VERSION ""

NS_ :

BS_:

BU_:

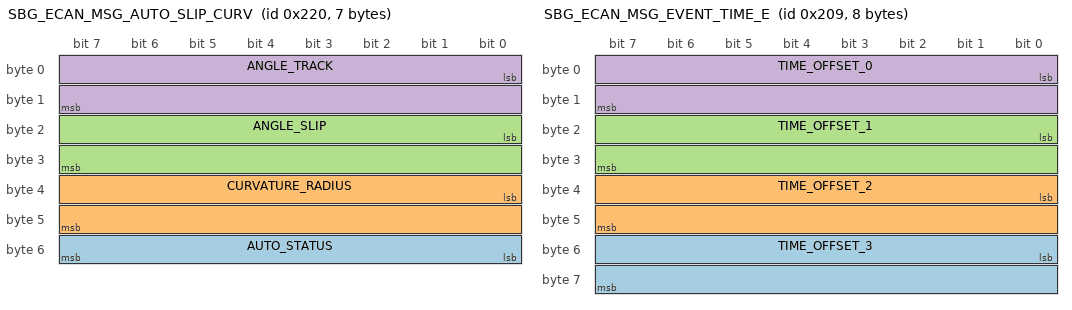
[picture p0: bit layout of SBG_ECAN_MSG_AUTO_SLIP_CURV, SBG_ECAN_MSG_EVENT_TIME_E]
BO_ 544 SBG_ECAN_MSG_AUTO_SLIP_CURV: 7 Vector__XXX
 SG_ AUTO_STATUS : 48|8@1+ (1,0) [0|255] "" Vector__XXX
 SG_ CURVATURE_RADIUS : 32|16@1+ (0.01,0) [0|655.35] "m" Vector__XXX
 SG_ ANGLE_SLIP : 16|16@1- (0.0001,0) [-3.2768|3.2767] "rad" Vector__XXX
 SG_ ANGLE_TRACK : 0|16@1- (0.0001,0) [-3.2768|3.2767] "rad" Vector__XXX

BO_ 521 SBG_ECAN_MSG_EVENT_TIME_E: 8 Vector__XXX
 SG_ TIME_OFFSET_3 : 48|16@1+ (1,0) [0|65535] "µs" Vector__XXX
 SG_ TIME_OFFSET_2 : 32|16@1+ (1,0) [0|65535] "µs" Vector__XXX
 SG_ TIME_OFFSET_1 : 16|16@1+ (1,0) [0|65535] "µs" Vector__XXX
 SG_ TIME_OFFSET_0 : 0|16@1+ (1,0) [0|65535] "µs" Vector__XXX

BO_ 520 SBG_ECAN_MSG_EVENT_INFO_E: 8 Vector__XXX
 SG_ STATUS : 32|16@1+ (1,0) [0|65535] "" Vector__XXX
 SG_ TIME_STAMP : 0|32@1+ (1,0) [0|4294970000] "µs" Vector__XXX

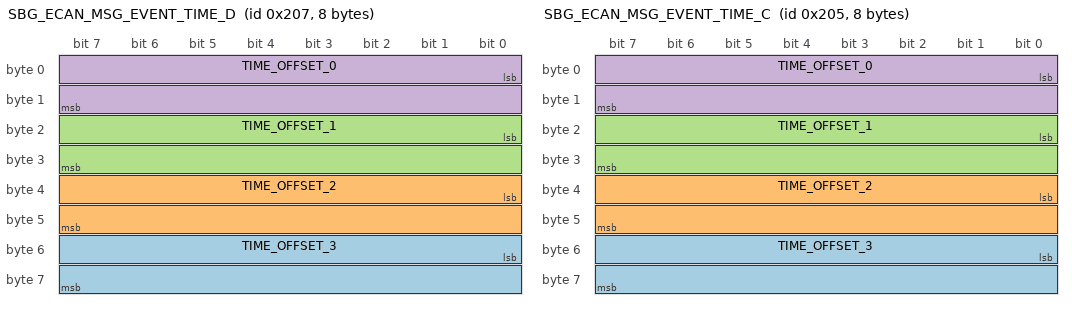
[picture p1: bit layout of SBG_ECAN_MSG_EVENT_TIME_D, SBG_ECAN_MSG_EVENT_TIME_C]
BO_ 519 SBG_ECAN_MSG_EVENT_TIME_D: 8 Vector__XXX
 SG_ TIME_OFFSET_3 : 48|16@1+ (1,0) [0|65535] "µs" Vector__XXX
 SG_ TIME_OFFSET_2 : 32|16@1+ (1,0) [0|65535] "µs" Vector__XXX
 SG_ TIME_OFFSET_1 : 16|16@1+ (1,0) [0|65535] "µs" Vector__XXX
 SG_ TIME_OFFSET_0 : 0|16@1+ (1,0) [0|65535] "µs" Vector__XXX

BO_ 518 SBG_ECAN_MSG_EVENT_INFO_D: 8 Vector__XXX
 SG_ STATUS : 32|16@1+ (1,0) [0|65535] "" Vector__XXX
 SG_ TIME_STAMP : 0|32@1+ (1,0) [0|4294970000] "µs" Vector__XXX

BO_ 517 SBG_ECAN_MSG_EVENT_TIME_C: 8 Vector__XXX
 SG_ TIME_OFFSET_3 : 48|16@1+ (1,0) [0|65535] "µs" Vector__XXX
 SG_ TIME_OFFSET_2 : 32|16@1+ (1,0) [0|65535] "µs" Vector__XXX
 SG_ TIME_OFFSET_1 : 16|16@1+ (1,0) [0|65535] "µs" Vector__XXX
 SG_ TIME_OFFSET_0 : 0|16@1+ (1,0) [0|65535] "µs" Vector__XXX

BO_ 516 SBG_ECAN_MSG_EVENT_INFO_C: 8 Vector__XXX
 SG_ STATUS : 32|16@1+ (1,0) [0|65535] "" Vector__XXX
 SG_ TIME_STAMP : 0|32@1+ (1,0) [0|4294970000] "µs" Vector__XXX

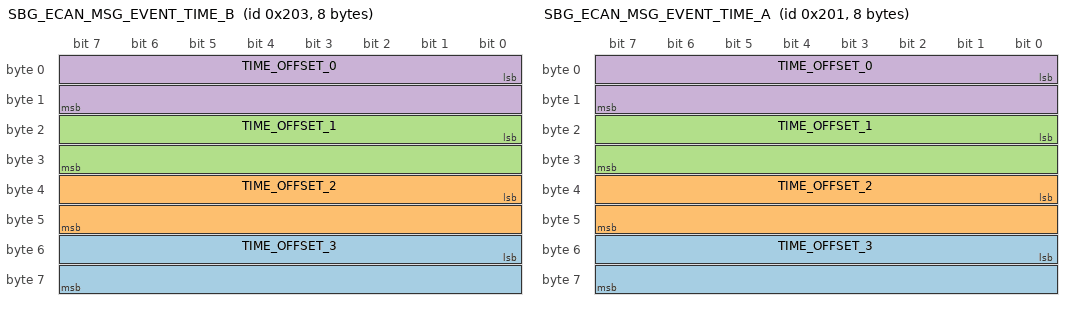
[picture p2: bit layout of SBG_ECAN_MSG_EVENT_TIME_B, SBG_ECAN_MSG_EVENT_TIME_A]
BO_ 515 SBG_ECAN_MSG_EVENT_TIME_B: 8 Vector__XXX
 SG_ TIME_OFFSET_3 : 48|16@1+ (1,0) [0|65535] "µs" Vector__XXX
 SG_ TIME_OFFSET_2 : 32|16@1+ (1,0) [0|65535] "µs" Vector__XXX
 SG_ TIME_OFFSET_1 : 16|16@1+ (1,0) [0|65535] "µs" Vector__XXX
 SG_ TIME_OFFSET_0 : 0|16@1+ (1,0) [0|65535] "µs" Vector__XXX

BO_ 514 SBG_ECAN_MSG_EVENT_INFO_B: 8 Vector__XXX
 SG_ STATUS : 32|16@1+ (1,0) [0|65535] "" Vector__XXX
 SG_ TIME_STAMP : 0|32@1+ (1,0) [0|4294970000] "µs" Vector__XXX

BO_ 513 SBG_ECAN_MSG_EVENT_TIME_A: 8 Vector__XXX
 SG_ TIME_OFFSET_3 : 48|16@1+ (1,0) [0|65535] "µs" Vector__XXX
 SG_ TIME_OFFSET_2 : 32|16@1+ (1,0) [0|65535] "µs" Vector__XXX
 SG_ TIME_OFFSET_1 : 16|16@1+ (1,0) [0|65535] "µs" Vector__XXX
 SG_ TIME_OFFSET_0 : 0|16@1+ (1,0) [0|65535] "µs" Vector__XXX

BO_ 512 SBG_ECAN_MSG_EVENT_INFO_A: 8 Vector__XXX
 SG_ STATUS : 32|16@1+ (1,0) [0|65535] "" Vector__XXX
 SG_ TIME_STAMP : 0|32@1+ (1,0) [0|4294970000] "µs" Vector__XXX

BO_ 396 SBG_ECAN_MSG_GPS2_POS_MON: 5 Vector__XXX
 SG_ UP_TIME : 8|32@1+ (1,0) [0|4294970000] "s" Vector__XXX
 SG_ NR_DIAG_REBOOTS : 0|1@1+ (1,0) [0|255] "" Vector__XXX

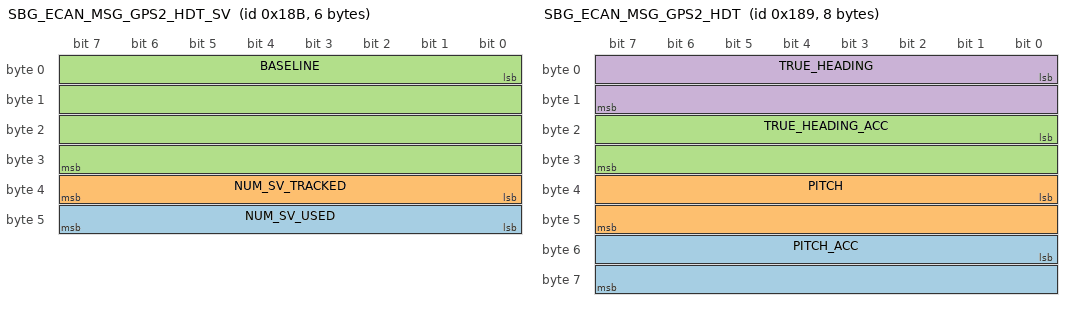
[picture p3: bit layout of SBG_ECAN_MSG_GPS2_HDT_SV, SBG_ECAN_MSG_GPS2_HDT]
BO_ 395 SBG_ECAN_MSG_GPS2_HDT_SV: 6 Vector__XXX
 SG_ NUM_SV_USED : 40|8@1+ (1,0) [0|255] "" Vector__XXX
 SG_ NUM_SV_TRACKED : 32|8@1+ (1,0) [0|255] "" Vector__XXX
 SG_ BASELINE : 0|32@1+ (1,0) [0|4294970000] "m" Vector__XXX

BO_ 394 SBG_ECAN_MSG_GPS2_POS_SECURITY_STATUS: 4 Vector__XXX
 SG_ STATUS : 32|32@1+ (1,0) [0|4294970000] "" Vector__XXX

BO_ 393 SBG_ECAN_MSG_GPS2_HDT: 8 Vector__XXX
 SG_ PITCH_ACC : 48|16@1+ (0.01,0) [0|655.35] "°" Vector__XXX
 SG_ PITCH : 32|16@1- (0.01,0) [-327.68|327.67] "°" Vector__XXX
 SG_ TRUE_HEADING_ACC : 16|16@1+ (0.01,0) [0|655.35] "°" Vector__XXX
 SG_ TRUE_HEADING : 0|16@1+ (0.01,0) [0|655.35] "°" Vector__XXX

BO_ 392 SBG_ECAN_MSG_GPS2_HDT_INFO: 6 Vector__XXX
 SG_ STATUS : 32|16@1+ (1,0) [0|65535] "" Vector__XXX
 SG_ TIME_STAMP : 0|32@1+ (1,0) [0|4294970000] "µs" Vector__XXX

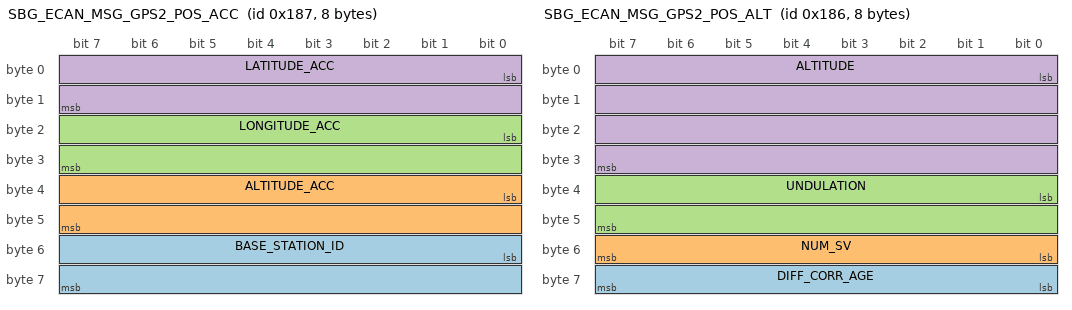
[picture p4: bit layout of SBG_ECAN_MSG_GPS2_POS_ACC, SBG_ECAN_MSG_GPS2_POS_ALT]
BO_ 391 SBG_ECAN_MSG_GPS2_POS_ACC: 8 Vector__XXX
 SG_ BASE_STATION_ID : 48|16@1+ (1,0) [0|65535] "" Vector__XXX
 SG_ ALTITUDE_ACC : 32|16@1+ (0.01,0) [0|655.35] "m" Vector__XXX
 SG_ LONGITUDE_ACC : 16|16@1+ (0.01,0) [0|655.35] "m" Vector__XXX
 SG_ LATITUDE_ACC : 0|16@1+ (0.01,0) [0|655.35] "m" Vector__XXX

BO_ 390 SBG_ECAN_MSG_GPS2_POS_ALT: 8 Vector__XXX
 SG_ DIFF_CORR_AGE : 56|8@1+ (1,0) [0|255] "s" Vector__XXX
 SG_ NUM_SV : 48|8@1+ (1,0) [0|255] "" Vector__XXX
 SG_ UNDULATION : 32|16@1- (0.005,0) [-163.84|163.835] "m" Vector__XXX
 SG_ ALTITUDE : 0|32@1- (0.001,0) [-2147480|2147480] "m" Vector__XXX

BO_ 389 SBG_ECAN_MSG_GPS2_POS: 8 Vector__XXX
 SG_ LONGITUDE : 32|32@1- (1E-007,0) [-214.7483648|214.7483647] "°" Vector__XXX
 SG_ LATITUDE : 0|32@1- (1E-007,0) [-214.7483648|214.7483647] "°" Vector__XXX

BO_ 388 SBG_ECAN_MSG_GPS2_POS_INFO: 8 Vector__XXX
 SG_ STATUS : 32|32@1+ (1,0) [0|4294970000] "" Vector__XXX
 SG_ TIME_STAMP : 0|32@1+ (1,0) [0|4294970000] "µs" Vector__XXX

BO_ 387 SBG_ECAN_MSG_GPS2_VEL_COURSE: 4 Vector__XXX
 SG_ COURSE_ACC : 16|16@1+ (0.01,0) [0|655.35] "°" Vector__XXX
 SG_ COURSE : 0|16@1+ (0.01,0) [0|655.35] "°" Vector__XXX

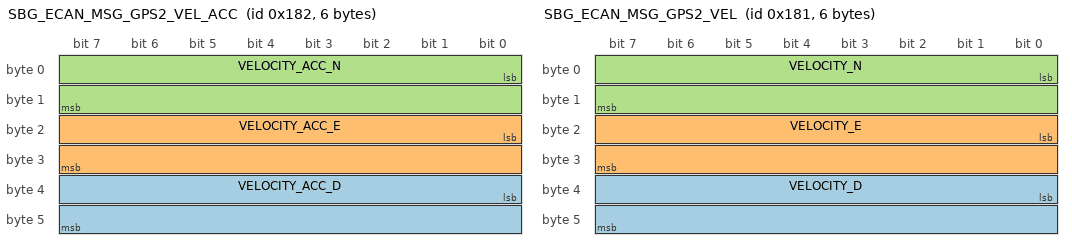
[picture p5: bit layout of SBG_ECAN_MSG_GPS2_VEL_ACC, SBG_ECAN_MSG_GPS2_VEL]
BO_ 386 SBG_ECAN_MSG_GPS2_VEL_ACC: 6 Vector__XXX
 SG_ VELOCITY_ACC_D : 32|16@1- (0.01,0) [-327.68|327.67] "m.s-1" Vector__XXX
 SG_ VELOCITY_ACC_E : 16|16@1- (0.01,0) [-327.68|327.67] "m.s-1" Vector__XXX
 SG_ VELOCITY_ACC_N : 0|16@1- (0.01,0) [-327.68|327.67] "m.s-1" Vector__XXX

BO_ 385 SBG_ECAN_MSG_GPS2_VEL: 6 Vector__XXX
 SG_ VELOCITY_D : 32|16@1- (0.01,0) [-327.68|327.67] "m.s-1" Vector__XXX
 SG_ VELOCITY_E : 16|16@1- (0.01,0) [-327.68|327.67] "m.s-1" Vector__XXX
 SG_ VELOCITY_N : 0|16@1- (0.01,0) [-327.68|327.67] "m.s-1" Vector__XXX

BO_ 384 SBG_ECAN_MSG_GPS2_VEL_INFO: 8 Vector__XXX
 SG_ STATUS : 32|32@1+ (1,0) [0|4294970000] "" Vector__XXX
 SG_ TIME_STAMP : 0|32@1+ (1,0) [0|4294970000] "µs" Vector__XXX

BO_ 380 SBG_ECAN_MSG_GPS1_POS_MON: 5 Vector__XXX
 SG_ UP_TIME : 8|32@1+ (1,0) [4294970000] "s" Vector__XXX
 SG_ NR_DIAG_REBOOTS : 0|1@1+ (1,0) [0|255] "" Vector__XXX

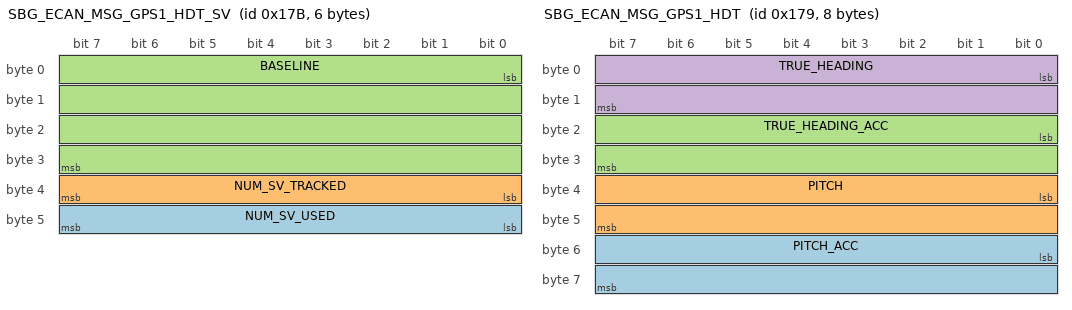
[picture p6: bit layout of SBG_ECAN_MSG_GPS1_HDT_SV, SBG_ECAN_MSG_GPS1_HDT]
BO_ 379 SBG_ECAN_MSG_GPS1_HDT_SV: 6 Vector__XXX
 SG_ NUM_SV_USED : 40|8@1+ (1,0) [0|255] "" Vector__XXX
 SG_ NUM_SV_TRACKED : 32|8@1+ (1,0) [0|255] "" Vector__XXX
 SG_ BASELINE : 0|32@1+ (1,0) [0|4294970000] "m" Vector__XXX

BO_ 378 SBG_ECAN_MSG_GPS1_POS_SECURITY_STATUS: 4 Vector__XXX
 SG_ STATUS : 32|32@1+ (1,0) [0|4294970000] "" Vector__XXX

BO_ 377 SBG_ECAN_MSG_GPS1_HDT: 8 Vector__XXX
 SG_ PITCH_ACC : 48|16@1+ (0.01,0) [0|655.35] "°" Vector__XXX
 SG_ PITCH : 32|16@1- (0.01,0) [-327.68|327.67] "°" Vector__XXX
 SG_ TRUE_HEADING_ACC : 16|16@1+ (0.01,0) [0|655.35] "°" Vector__XXX
 SG_ TRUE_HEADING : 0|16@1+ (0.01,0) [0|655.35] "°" Vector__XXX

BO_ 376 SBG_ECAN_MSG_GPS1_HDT_INFO: 6 Vector__XXX
 SG_ STATUS : 32|16@1+ (1,0) [0|65535] "" Vector__XXX
 SG_ TIME_STAMP : 0|32@1+ (1,0) [0|4294970000] "µs" Vector__XXX

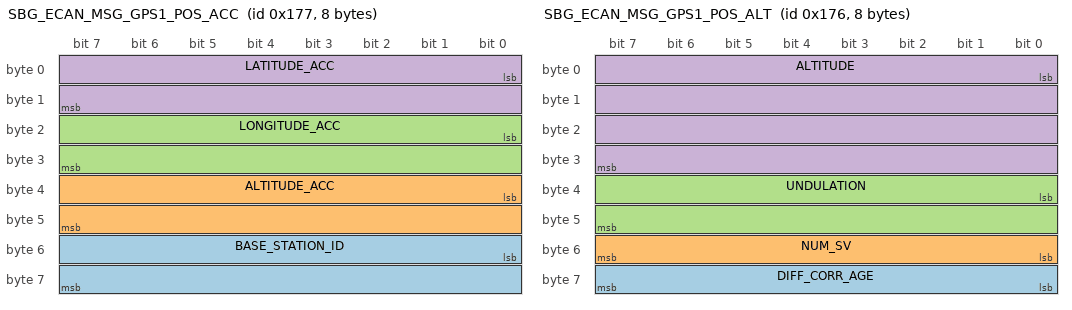
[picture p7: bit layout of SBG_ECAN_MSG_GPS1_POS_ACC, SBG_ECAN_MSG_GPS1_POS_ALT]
BO_ 375 SBG_ECAN_MSG_GPS1_POS_ACC: 8 Vector__XXX
 SG_ BASE_STATION_ID : 48|16@1+ (1,0) [0|65535] "" Vector__XXX
 SG_ ALTITUDE_ACC : 32|16@1+ (0.01,0) [0|655.35] "m" Vector__XXX
 SG_ LONGITUDE_ACC : 16|16@1+ (0.01,0) [0|655.35] "m" Vector__XXX
 SG_ LATITUDE_ACC : 0|16@1+ (0.01,0) [0|655.35] "m" Vector__XXX

BO_ 374 SBG_ECAN_MSG_GPS1_POS_ALT: 8 Vector__XXX
 SG_ DIFF_CORR_AGE : 56|8@1+ (1,0) [0|255] "s" Vector__XXX
 SG_ NUM_SV : 48|8@1+ (1,0) [0|255] "" Vector__XXX
 SG_ UNDULATION : 32|16@1- (0.005,0) [-163.84|163.835] "m" Vector__XXX
 SG_ ALTITUDE : 0|32@1- (0.001,0) [-2147480|2147480] "m" Vector__XXX

BO_ 373 SBG_ECAN_MSG_GPS1_POS: 8 Vector__XXX
 SG_ LONGITUDE : 32|32@1- (1E-007,0) [-214.7483648|214.7483647] "°" Vector__XXX
 SG_ LATITUDE : 0|32@1- (1E-007,0) [-214.7483648|214.7483647] "°" Vector__XXX

BO_ 372 SBG_ECAN_MSG_GPS1_POS_INFO: 8 Vector__XXX
 SG_ STATUS : 32|32@1+ (1,0) [0|4294970000] "" Vector__XXX
 SG_ TIME_STAMP : 0|32@1+ (1,0) [0|4294970000] "µs" Vector__XXX

BO_ 371 SBG_ECAN_MSG_GPS1_VEL_COURSE: 4 Vector__XXX
 SG_ COURSE_ACC : 16|16@1+ (0.01,0) [0|655.35] "°" Vector__XXX
 SG_ COURSE : 0|16@1+ (0.01,0) [0|655.35] "°" Vector__XXX

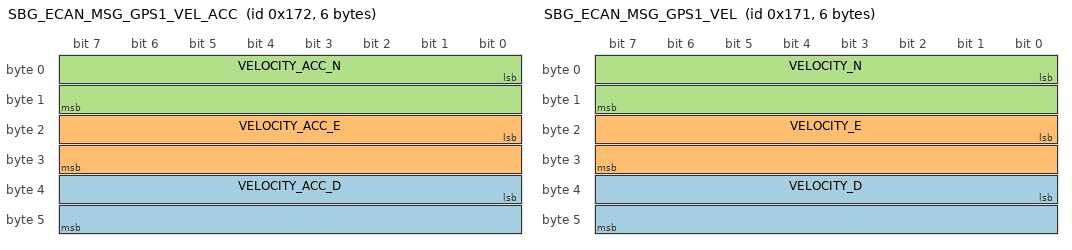
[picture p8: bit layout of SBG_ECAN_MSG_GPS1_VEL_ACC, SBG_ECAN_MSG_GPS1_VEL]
BO_ 370 SBG_ECAN_MSG_GPS1_VEL_ACC: 6 Vector__XXX
 SG_ VELOCITY_ACC_D : 32|16@1- (0.01,0) [-327.68|327.67] "m.s-1" Vector__XXX
 SG_ VELOCITY_ACC_E : 16|16@1- (0.01,0) [-327.68|327.67] "m.s-1" Vector__XXX
 SG_ VELOCITY_ACC_N : 0|16@1- (0.01,0) [-327.68|327.67] "m.s-1" Vector__XXX

BO_ 369 SBG_ECAN_MSG_GPS1_VEL: 6 Vector__XXX
 SG_ VELOCITY_D : 32|16@1- (0.01,0) [-327.68|327.67] "m.s-1" Vector__XXX
 SG_ VELOCITY_E : 16|16@1- (0.01,0) [-327.68|327.67] "m.s-1" Vector__XXX
 SG_ VELOCITY_N : 0|16@1- (0.01,0) [-327.68|327.67] "m.s-1" Vector__XXX

BO_ 368 SBG_ECAN_MSG_GPS1_VEL_INFO: 8 Vector__XXX
 SG_ STATUS : 32|32@1+ (1,0) [0|4294970000] "" Vector__XXX
 SG_ TIME_STAMP : 0|32@1+ (1,0) [0|4294970000] "µs" Vector__XXX

BO_ 359 SBG_ECAN_MSG_DEPTH_ALTITUDE: 8 Vector__XXX
 SG_ DEPTH : 32|32@1- (0.001,0) [-2147480|2147480] "m" Vector__XXX
 SG_ PRESSURE_ABS : 0|32@1+ (0.1,0) [0|429497000] "Pa" Vector__XXX

BO_ 358 SBG_ECAN_MSG_DEPTH_INFO: 5 Vector__XXX
 SG_ DEPTH_STATUS : 32|8@1+ (1,0) [0|255] "" Vector__XXX
 SG_ TIME_STAMP : 0|32@1+ (1,0) [0|4294970000] "us" Vector__XXX

BO_ 356 SBG_ECAN_MSG_AIR_DATA_AIRSPEED: 6 Vector__XXX
 SG_ AIRSPEED : 32|16@1- (0.01,0) [-327.68|327.67] "m.s-1" Vector__XXX
 SG_ PRESSURE_DIFF : 0|32@1- (0.001,0) [-2147483.648|2147483.647] "Pa" Vector__XXX

BO_ 355 SBG_ECAN_MSG_AIR_DATA_ALTITUDE: 8 Vector__XXX
 SG_ ALTITUDE : 32|32@1- (0.001,0) [-2147483.648|2147483.647] "m" Vector__XXX
 SG_ PRESSURE_ABS : 0|32@1+ (0.001,0) [0|4294967.295] "Pa" Vector__XXX

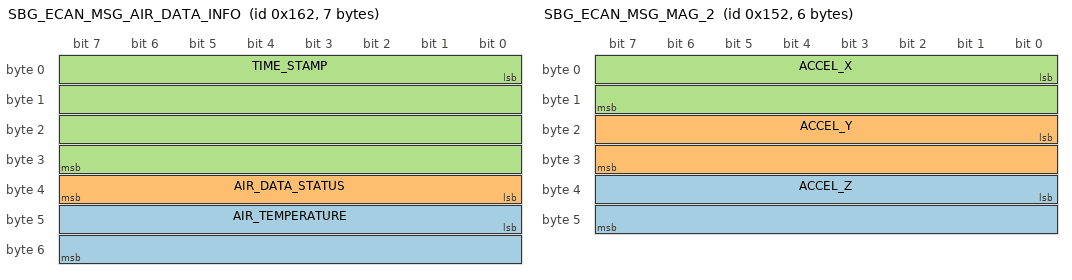
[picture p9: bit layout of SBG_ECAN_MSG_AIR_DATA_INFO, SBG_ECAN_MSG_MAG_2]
BO_ 354 SBG_ECAN_MSG_AIR_DATA_INFO: 7 Vector__XXX
 SG_ AIR_TEMPERATURE : 40|16@1- (0.01,0) [-327.68|327.67] "°C" Vector__XXX
 SG_ AIR_DATA_STATUS : 32|8@1+ (1,0) [0|255] "" Vector__XXX
 SG_ TIME_STAMP : 0|32@1+ (1,0) [0|4294970000] "us" Vector__XXX

BO_ 353 SBG_ECAN_MSG_ODO_VEL: 2 Vector__XXX
 SG_ VELOCITY : 0|16@1- (0.01,0) [-327.68|327.67] "m.s-1" Vector__XXX

BO_ 352 SBG_ECAN_MSG_ODO_INFO: 6 Vector__XXX
 SG_ ODO_STATUS : 32|16@1+ (1,0) [0|65535] "" Vector__XXX
 SG_ TIME_STAMP : 0|32@1+ (1,0) [0|4294970000] "µs" Vector__XXX

BO_ 338 SBG_ECAN_MSG_MAG_2: 6 Vector__XXX
 SG_ ACCEL_Z : 32|16@1- (0.01,0) [-327.68|327.67] "m.s-2" Vector__XXX
 SG_ ACCEL_Y : 16|16@1- (0.01,0) [-327.68|327.67] "m.s-2" Vector__XXX
 SG_ ACCEL_X : 0|16@1- (0.01,0) [-327.68|327.67] "m.s-2" Vector__XXX

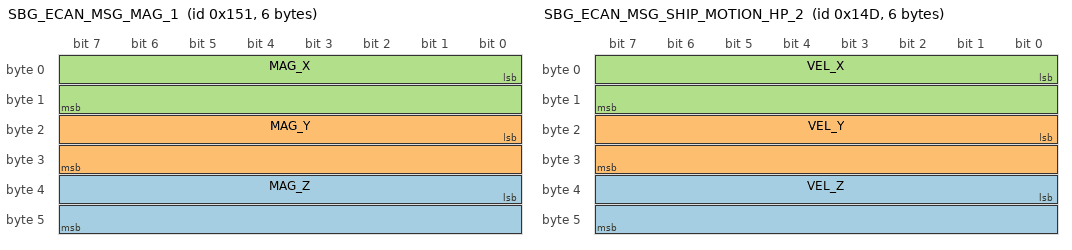
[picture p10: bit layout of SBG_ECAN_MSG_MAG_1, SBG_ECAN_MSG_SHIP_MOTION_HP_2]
BO_ 337 SBG_ECAN_MSG_MAG_1: 6 Vector__XXX
 SG_ MAG_Z : 32|16@1- (0.001,0) [-32.768|32.767] "a.u." Vector__XXX
 SG_ MAG_Y : 16|16@1- (0.001,0) [-32.768|32.767] "a.u." Vector__XXX
 SG_ MAG_X : 0|16@1- (0.001,0) [-32.768|32.767] "a.u." Vector__XXX

BO_ 336 SBG_ECAN_MSG_MAG_0: 6 Vector__XXX
 SG_ STATUS : 32|16@1+ (1,0) [0|65535] "" Vector__XXX
 SG_ TIME_STAMP : 0|32@1+ (1,0) [0|4294970000] "µs" Vector__XXX

BO_ 333 SBG_ECAN_MSG_SHIP_MOTION_HP_2: 6 Vector__XXX
 SG_ VEL_Z : 32|16@1- (0.01,0) [-327.68|327.67] "m.s-1" Vector__XXX
 SG_ VEL_Y : 16|16@1- (0.01,0) [-327.68|327.67] "m.s-1" Vector__XXX
 SG_ VEL_X : 0|16@1- (0.01,0) [-327.68|327.67] "m.s-1" Vector__XXX

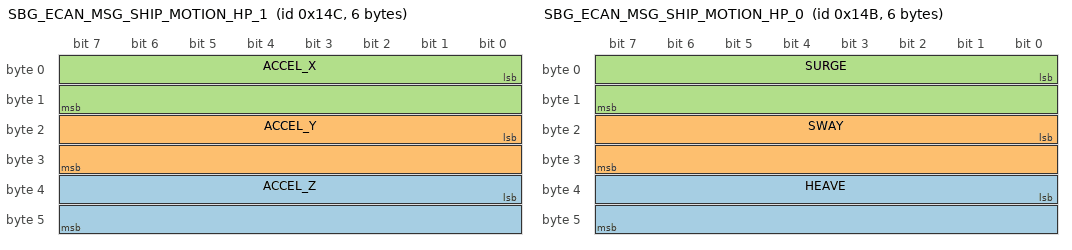
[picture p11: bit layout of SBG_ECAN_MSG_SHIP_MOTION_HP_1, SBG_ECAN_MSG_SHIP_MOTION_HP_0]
BO_ 332 SBG_ECAN_MSG_SHIP_MOTION_HP_1: 6 Vector__XXX
 SG_ ACCEL_Z : 32|16@1- (0.01,0) [-327.68|327.67] "m.s-2" Vector__XXX
 SG_ ACCEL_Y : 16|16@1- (0.01,0) [-327.68|327.67] "m.s-2" Vector__XXX
 SG_ ACCEL_X : 0|16@1- (0.01,0) [-327.68|327.67] "m.s-2" Vector__XXX

BO_ 331 SBG_ECAN_MSG_SHIP_MOTION_HP_0: 6 Vector__XXX
 SG_ HEAVE : 32|16@1- (0.001,0) [-32.768|32.767] "m" Vector__XXX
 SG_ SWAY : 16|16@1- (0.001,0) [-32.768|32.767] "m" Vector__XXX
 SG_ SURGE : 0|16@1- (0.001,0) [-32.768|32.767] "m" Vector__XXX

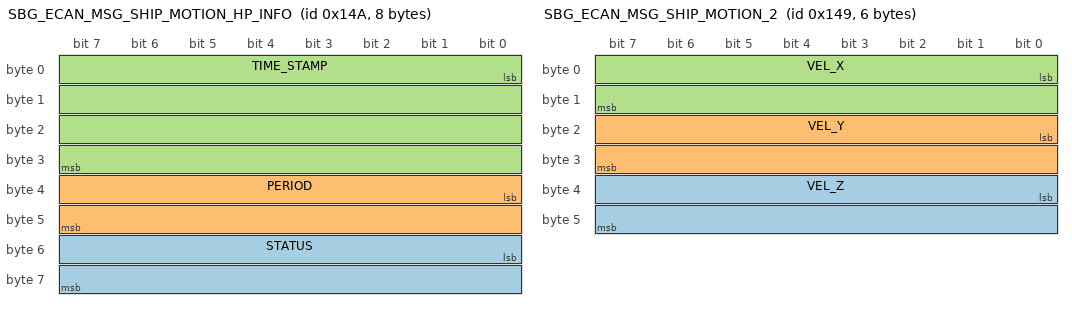
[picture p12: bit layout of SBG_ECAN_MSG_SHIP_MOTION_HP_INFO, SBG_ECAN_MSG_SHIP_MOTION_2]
BO_ 330 SBG_ECAN_MSG_SHIP_MOTION_HP_INFO: 8 Vector__XXX
 SG_ STATUS : 48|16@1+ (1,0) [0|65535] "" Vector__XXX
 SG_ PERIOD : 32|16@1+ (0.01,0) [0|655.35] "s" Vector__XXX
 SG_ TIME_STAMP : 0|32@1+ (1,0) [0|4294970000] "µs" Vector__XXX

BO_ 329 SBG_ECAN_MSG_SHIP_MOTION_2: 6 Vector__XXX
 SG_ VEL_Z : 32|16@1- (0.01,0) [-327.68|327.67] "m.s-1" Vector__XXX
 SG_ VEL_Y : 16|16@1- (0.01,0) [-327.68|327.67] "m.s-1" Vector__XXX
 SG_ VEL_X : 0|16@1- (0.01,0) [-327.68|327.67] "m.s-1" Vector__XXX

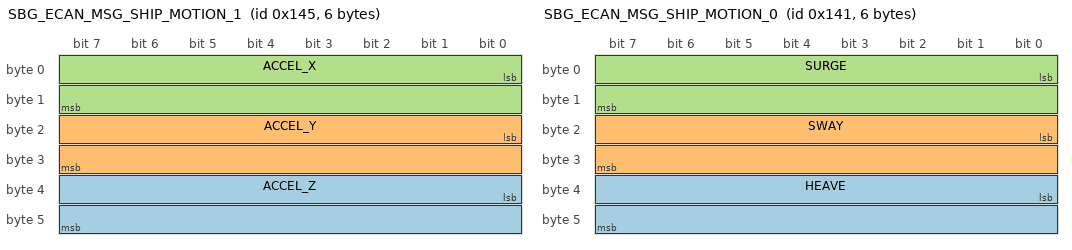
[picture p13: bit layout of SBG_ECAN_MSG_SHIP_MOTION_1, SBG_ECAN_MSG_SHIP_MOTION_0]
BO_ 325 SBG_ECAN_MSG_SHIP_MOTION_1: 6 Vector__XXX
 SG_ ACCEL_Z : 32|16@1- (0.01,0) [-327.68|327.67] "m.s-2" Vector__XXX
 SG_ ACCEL_Y : 16|16@1- (0.01,0) [-327.68|327.67] "m.s-2" Vector__XXX
 SG_ ACCEL_X : 0|16@1- (0.01,0) [-327.68|327.67] "m.s-2" Vector__XXX

BO_ 321 SBG_ECAN_MSG_SHIP_MOTION_0: 6 Vector__XXX
 SG_ HEAVE : 32|16@1- (0.001,0) [-32.768|32.767] "m" Vector__XXX
 SG_ SWAY : 16|16@1- (0.001,0) [-32.768|32.767] "m" Vector__XXX
 SG_ SURGE : 0|16@1- (0.001,0) [-32.768|32.767] "m" Vector__XXX

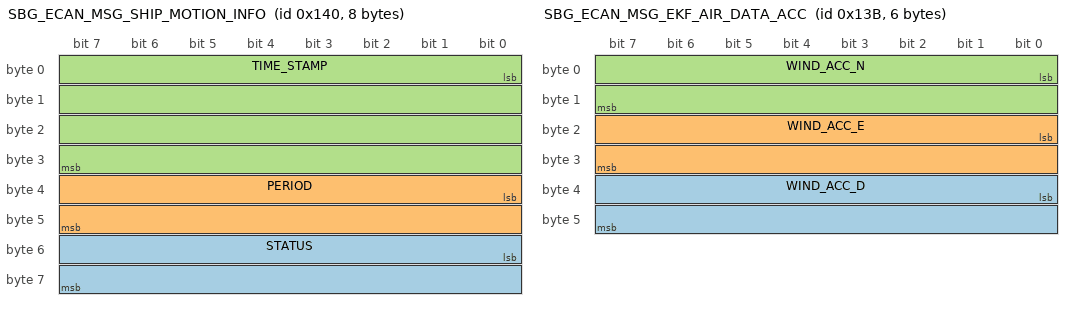
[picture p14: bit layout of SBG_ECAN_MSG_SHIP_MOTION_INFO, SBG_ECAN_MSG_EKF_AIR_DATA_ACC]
BO_ 320 SBG_ECAN_MSG_SHIP_MOTION_INFO: 8 Vector__XXX
 SG_ STATUS : 48|16@1+ (1,0) [0|65535] "" Vector__XXX
 SG_ PERIOD : 32|16@1+ (0.01,0) [0|655.35] "s" Vector__XXX
 SG_ TIME_STAMP : 0|32@1+ (1,0) [0|4294970000] "µs" Vector__XXX

BO_ 315 SBG_ECAN_MSG_EKF_AIR_DATA_ACC: 6 Vector__XXX
 SG_ WIND_ACC_D : 32|16@1+ (0.01,0) [0|655.35] "m.s-1" Vector__XXX
 SG_ WIND_ACC_E : 16|16@1+ (0.01,0) [0|655.35] "m.s-1" Vector__XXX
 SG_ WIND_ACC_N : 0|16@1+ (0.01,0) [0|655.35] "m.s-1" Vector__XXX

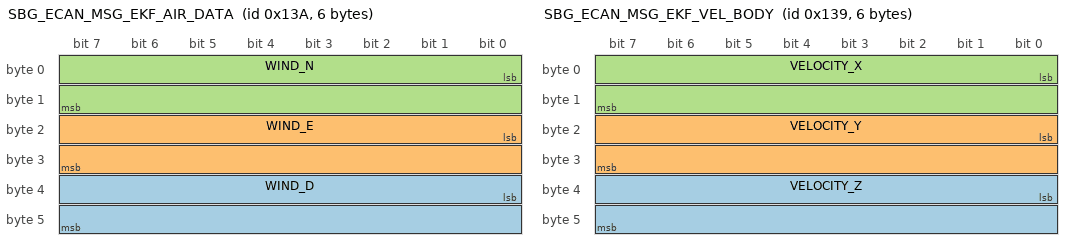
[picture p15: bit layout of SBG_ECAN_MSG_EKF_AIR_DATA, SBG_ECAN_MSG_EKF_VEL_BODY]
BO_ 314 SBG_ECAN_MSG_EKF_AIR_DATA: 6 Vector__XXX
 SG_ WIND_D : 32|16@1- (0.01,0) [-327.68|327.67] "m.s-1" Vector__XXX
 SG_ WIND_E : 16|16@1- (0.01,0) [-327.68|327.67] "m.s-1" Vector__XXX
 SG_ WIND_N : 0|16@1- (0.01,0) [-327.68|327.67] "m.s-1" Vector__XXX

BO_ 313 SBG_ECAN_MSG_EKF_VEL_BODY: 6 Vector__XXX
 SG_ VELOCITY_Z : 32|16@1- (0.01,0) [-327.68|327.67] "m.s-1" Vector__XXX
 SG_ VELOCITY_Y : 16|16@1- (0.01,0) [-327.68|327.67] "m.s-1" Vector__XXX
 SG_ VELOCITY_X : 0|16@1- (0.01,0) [-327.68|327.67] "m.s-1" Vector__XXX

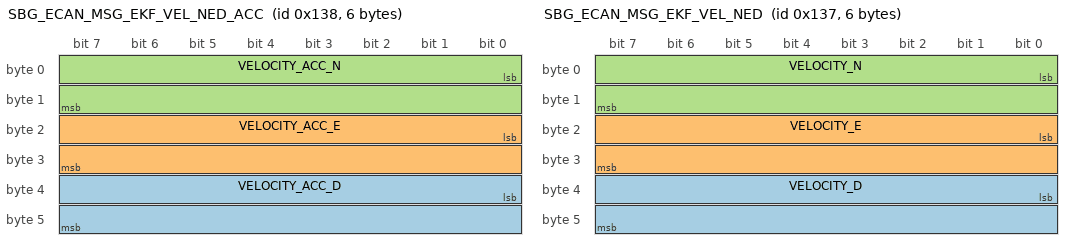
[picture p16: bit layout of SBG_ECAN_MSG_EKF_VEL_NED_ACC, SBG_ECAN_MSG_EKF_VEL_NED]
BO_ 312 SBG_ECAN_MSG_EKF_VEL_NED_ACC: 6 Vector__XXX
 SG_ VELOCITY_ACC_D : 32|16@1- (0.01,0) [-327.68|327.67] "m.s-1" Vector__XXX
 SG_ VELOCITY_ACC_E : 16|16@1- (0.01,0) [-327.68|327.67] "m.s-1" Vector__XXX
 SG_ VELOCITY_ACC_N : 0|16@1- (0.01,0) [-327.68|327.67] "m.s-1" Vector__XXX

BO_ 311 SBG_ECAN_MSG_EKF_VEL_NED: 6 Vector__XXX
 SG_ VELOCITY_D : 32|16@1- (0.01,0) [-327.68|327.67] "m.s-1" Vector__XXX
 SG_ VELOCITY_E : 16|16@1- (0.01,0) [-327.68|327.67] "m.s-1" Vector__XXX
 SG_ VELOCITY_N : 0|16@1- (0.01,0) [-327.68|327.67] "m.s-1" Vector__XXX

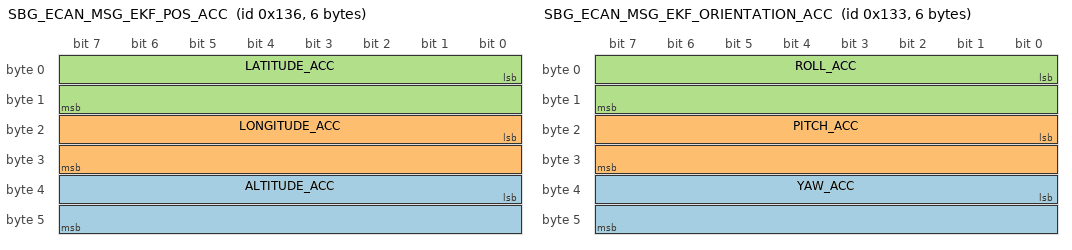
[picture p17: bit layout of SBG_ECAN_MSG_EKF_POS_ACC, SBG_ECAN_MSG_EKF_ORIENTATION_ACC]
BO_ 310 SBG_ECAN_MSG_EKF_POS_ACC: 6 Vector__XXX
 SG_ ALTITUDE_ACC : 32|16@1+ (0.01,0) [0|655.35] "m" Vector__XXX
 SG_ LONGITUDE_ACC : 16|16@1+ (0.01,0) [0|655.35] "m" Vector__XXX
 SG_ LATITUDE_ACC : 0|16@1+ (0.01,0) [0|655.35] "m" Vector__XXX

BO_ 309 SBG_ECAN_MSG_EKF_ALTITUDE: 6 Vector__XXX
 SG_ UNDULATION : 32|16@1- (0.005,0) [-163.84|163.835] "m" Vector__XXX
 SG_ ALTITUDE : 0|32@1- (0.001,0) [-2147480|2147480] "m" Vector__XXX

BO_ 308 SBG_ECAN_MSG_EKF_POS: 8 Vector__XXX
 SG_ LONGITUDE : 32|32@1- (1E-007,0) [-214.7483648|214.7483647] "°" Vector__XXX
 SG_ LATITUDE : 0|32@1- (1E-007,0) [-214.7483648|214.7483647] "°" Vector__XXX

BO_ 307 SBG_ECAN_MSG_EKF_ORIENTATION_ACC: 6 Vector__XXX
 SG_ YAW_ACC : 32|16@1+ (0.0001,0) [0|6.5535] "rad" Vector__XXX
 SG_ PITCH_ACC : 16|16@1+ (0.0001,0) [0|6.5535] "rad" Vector__XXX
 SG_ ROLL_ACC : 0|16@1+ (0.0001,0) [0|6.5535] "rad" Vector__XXX

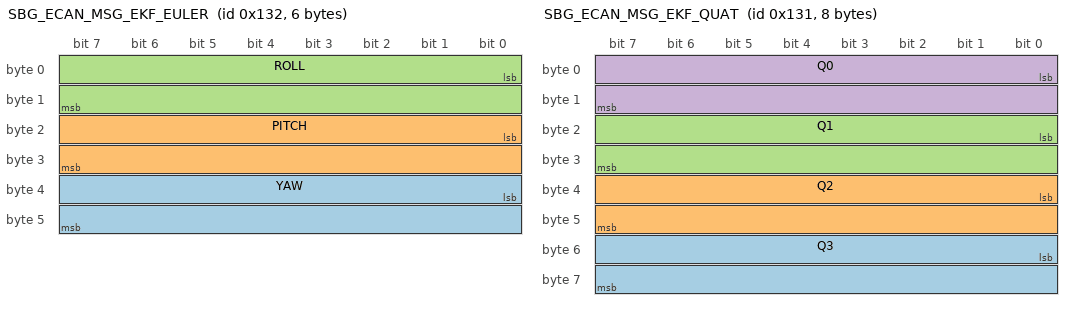
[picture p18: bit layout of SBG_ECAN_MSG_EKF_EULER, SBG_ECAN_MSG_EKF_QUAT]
BO_ 306 SBG_ECAN_MSG_EKF_EULER: 6 Vector__XXX
 SG_ YAW : 32|16@1- (0.0001,0) [-3.2768|3.2767] "rad" Vector__XXX
 SG_ PITCH : 16|16@1- (0.0001,0) [-3.2768|3.2767] "rad" Vector__XXX
 SG_ ROLL : 0|16@1- (0.0001,0) [-3.2768|3.2767] "rad" Vector__XXX

BO_ 305 SBG_ECAN_MSG_EKF_QUAT: 8 Vector__XXX
 SG_ Q3 : 48|16@1- (3.05185094759972E-005,0) [-1|1] "" Vector__XXX
 SG_ Q2 : 32|16@1- (3.05185094759972E-005,0) [-1|1] "" Vector__XXX
 SG_ Q1 : 16|16@1- (3.05185094759972E-005,0) [-1|1] "" Vector__XXX
 SG_ Q0 : 0|16@1- (3.05185094759972E-005,0) [-1|1] "" Vector__XXX

BO_ 304 SBG_ECAN_MSG_EKF_INFO: 4 Vector__XXX
 SG_ TIME_STAMP : 0|32@1+ (1,0) [0|4294970000] "µs" Vector__XXX

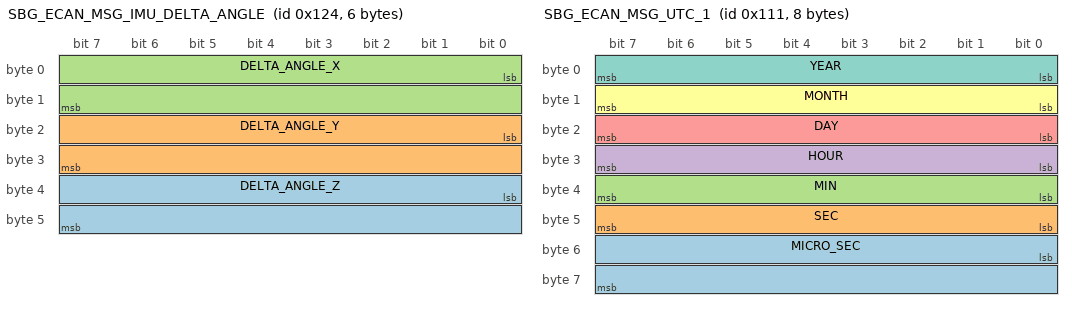
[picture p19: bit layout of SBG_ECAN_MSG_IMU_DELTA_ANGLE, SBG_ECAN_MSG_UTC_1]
BO_ 292 SBG_ECAN_MSG_IMU_DELTA_ANGLE: 6 Vector__XXX
 SG_ DELTA_ANGLE_Z : 32|16@1- (0.001,0) [-32.768|32.767] "rad.s-1" Vector__XXX
 SG_ DELTA_ANGLE_Y : 16|16@1- (0.001,0) [-32.768|32.767] "rad.s-1" Vector__XXX
 SG_ DELTA_ANGLE_X : 0|16@1- (0.001,0) [-32.768|32.767] "rad.s-1" Vector__XXX

BO_ 291 SBG_ECAN_MSG_IMU_DELTA_VEL: 6 Vector__XXX
 SG_ DELTA_VEL_Z : 32|16@1- (0.01,0) [-327.68|327.67] "m.s-2" Vector__XXX
 SG_ DELTA_VEL_Y : 16|16@1- (0.01,0) [-327.68|327.67] "m.s-2" Vector__XXX
 SG_ DELTA_VEL_X : 0|16@1- (0.01,0) [-327.68|327.67] "m.s-2" Vector__XXX

BO_ 290 SBG_ECAN_MSG_IMU_GYRO: 6 Vector__XXX
 SG_ GYRO_Z : 32|16@1- (0.001,0) [-32.768|32.767] "rad.s-1" Vector__XXX
 SG_ GYRO_Y : 16|16@1- (0.001,0) [-32.768|32.767] "rad.s-1" Vector__XXX
 SG_ GYRO_X : 0|16@1- (0.001,0) [-32.768|32.767] "rad.s-1" Vector__XXX

BO_ 289 SBG_ECAN_MSG_IMU_ACCEL: 6 Vector__XXX
 SG_ ACCEL_Z : 32|16@1- (0.01,0) [-327.68|327.67] "m.s-2" Vector__XXX
 SG_ ACCEL_Y : 16|16@1- (0.01,0) [-327.68|327.67] "m.s-2" Vector__XXX
 SG_ ACCEL_X : 0|16@1- (0.01,0) [-327.68|327.67] "m.s-2" Vector__XXX

BO_ 288 SBG_ECAN_MSG_IMU_INFO: 8 Vector__XXX
 SG_ TEMPERATURE : 48|16@1- (0.01,0) [-327.68|327.67] "°C" Vector__XXX
 SG_ STATUS : 32|16@1+ (1,0) [0|65535] "" Vector__XXX
 SG_ TIME_STAMP : 0|32@1+ (1,0) [0|4294970000] "µs" Vector__XXX

BO_ 273 SBG_ECAN_MSG_UTC_1: 8 Vector__XXX
 SG_ MICRO_SEC : 48|16@1+ (100,0) [0|6553500] "us" Vector__XXX
 SG_ SEC : 40|8@1+ (1,0) [0|255] "s" Vector__XXX
 SG_ MIN : 32|8@1+ (1,0) [0|255] "min" Vector__XXX
 SG_ HOUR : 24|8@1+ (1,0) [0|255] "h" Vector__XXX
 SG_ DAY : 16|8@1+ (1,0) [0|255] "d" Vector__XXX
 SG_ MONTH : 8|8@1+ (1,0) [0|255] "month" Vector__XXX
 SG_ YEAR : 0|8@1+ (1,2000) [2000|2255] "year" Vector__XXX

BO_ 272 SBG_ECAN_MSG_UTC_0: 8 Vector__XXX
 SG_ GPS_TOW : 32|32@1+ (1,0) [0|4294970000] "ms" Vector__XXX
 SG_ TIME_STAMP : 0|32@1+ (1,0) [0|4294970000] "µs" Vector__XXX

BO_ 258 SBG_ECAN_MSG_STATUS_03: 6 Vector__XXX
 SG_ HEAVE_STATUS : 32|16@1+ (1,0) [0|65535] "" Vector__XXX
 SG_ SOLUTION : 0|32@1+ (1,0) [0|4294970000] "" Vector__XXX

BO_ 257 SBG_ECAN_MSG_STATUS_02: 8 Vector__XXX
 SG_ AIDING : 32|32@1+ (1,0) [0|4294970000] "" Vector__XXX
 SG_ COM : 0|32@1+ (1,0) [0|4294970000] "" Vector__XXX

BO_ 256 SBG_ECAN_MSG_STATUS_01: 8 Vector__XXX
 SG_ CLOCK : 48|16@1+ (1,0) [0|65535] "" Vector__XXX
 SG_ GENERAL : 32|16@1+ (1,0) [0|65535] "" Vector__XXX
 SG_ TIME_STAMP : 0|32@1+ (1,0) [0|4294970000] "µs" Vector__XXX
